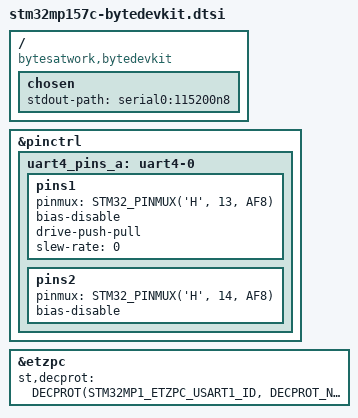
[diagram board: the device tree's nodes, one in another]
// SPDX-License-Identifier: GPL-2.0
/*
 *  Copyright (C) 2024 bytes at work AG - http://www.bytesatwork.ch
 */

/dts-v1/;

#include "stm32mp157.dtsi"
#include "stm32mp15xc.dtsi"
#include "stm32mp15-pinctrl.dtsi"
#include "stm32mp15xxac-pinctrl.dtsi"
#include "stm32mp15xx-dkx.dtsi"

/ {
	compatible = "bytesatwork,bytedevkit",
		     "bytesatwork,m5",
		     "st,stm32mp157";

	chosen {
		stdout-path = "serial0:115200n8";
	};
};

&pinctrl {
	uart4_pins_a: uart4-0 {
		pins1 {
			pinmux = <STM32_PINMUX('H', 13, AF8)>; /* UART4_TX */
			bias-disable;
			drive-push-pull;
			slew-rate = <0>;
		};
		pins2 {
			pinmux = <STM32_PINMUX('H', 14, AF8)>; /* UART4_RX */
			bias-disable;
		};
	};
};

&etzpc {
	st,decprot = <
		DECPROT(STM32MP1_ETZPC_USART1_ID, DECPROT_NS_RW, DECPROT_UNLOCK)
		DECPROT(STM32MP1_ETZPC_SPI6_ID, DECPROT_NS_RW, DECPROT_UNLOCK)
		DECPROT(STM32MP1_ETZPC_I2C4_ID, DECPROT_NS_RW, DECPROT_UNLOCK)
		DECPROT(STM32MP1_ETZPC_I2C6_ID, DECPROT_NS_RW, DECPROT_UNLOCK)
		DECPROT(STM32MP1_ETZPC_RNG1_ID, DECPROT_S_RW, DECPROT_UNLOCK)
		DECPROT(STM32MP1_ETZPC_HASH1_ID, DECPROT_NS_RW, DECPROT_UNLOCK)
		DECPROT(STM32MP1_ETZPC_CRYP1_ID, DECPROT_NS_RW, DECPROT_UNLOCK)
		DECPROT(STM32MP1_ETZPC_DDRCTRL_ID, DECPROT_NS_R_S_W, DECPROT_LOCK)
		DECPROT(STM32MP1_ETZPC_DDRPHYC_ID, DECPROT_NS_R_S_W, DECPROT_LOCK)
		DECPROT(STM32MP1_ETZPC_STGENC_ID, DECPROT_S_RW, DECPROT_LOCK)
		DECPROT(STM32MP1_ETZPC_BKPSRAM_ID, DECPROT_S_RW, DECPROT_LOCK)
		DECPROT(STM32MP1_ETZPC_IWDG1_ID, DECPROT_S_RW, DECPROT_LOCK)
	>;
};

